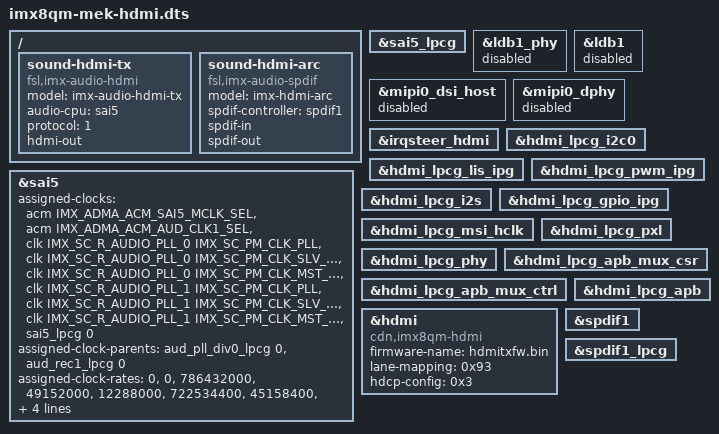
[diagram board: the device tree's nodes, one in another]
// SPDX-License-Identifier: GPL-2.0+
/*
 * Copyright 2019 NXP
 *	Sandor Yu <Sandor.yu@nxp.com>
 */
 /* HDMI, LVDS1 and MIPI DSI1. LVDS0 and MIPI0 are disabled */

/dts-v1/;

#include "imx8qm-mek-rpmsg.dts"

/ {
    sound-hdmi-tx {
        compatible = "fsl,imx-audio-hdmi";
        model = "imx-audio-hdmi-tx";
        audio-cpu = <&sai5>;
        protocol = <1>;
        hdmi-out;
    };

	sound-hdmi-arc {
		compatible = "fsl,imx-audio-spdif";
		model = "imx-hdmi-arc";
		spdif-controller = <&spdif1>;
		spdif-in;
		spdif-out;
	};
};

&sai5 {
	assigned-clocks = <&acm IMX_ADMA_ACM_SAI5_MCLK_SEL>,
			<&acm IMX_ADMA_ACM_AUD_CLK1_SEL>,
			<&clk IMX_SC_R_AUDIO_PLL_0 IMX_SC_PM_CLK_PLL>,
			<&clk IMX_SC_R_AUDIO_PLL_0 IMX_SC_PM_CLK_SLV_BUS>,
			<&clk IMX_SC_R_AUDIO_PLL_0 IMX_SC_PM_CLK_MST_BUS>,
			<&clk IMX_SC_R_AUDIO_PLL_1 IMX_SC_PM_CLK_PLL>,
			<&clk IMX_SC_R_AUDIO_PLL_1 IMX_SC_PM_CLK_SLV_BUS>,
			<&clk IMX_SC_R_AUDIO_PLL_1 IMX_SC_PM_CLK_MST_BUS>,
			<&sai5_lpcg 0>;
	assigned-clock-parents = <&aud_pll_div0_lpcg 0>, <&aud_rec1_lpcg 0>;
	assigned-clock-rates = <0>, <0>, <786432000>, <49152000>, <12288000>,
				 <722534400>, <45158400>, <11289600>,
				<49152000>;
	clocks = <&sai5_lpcg 1>,
		<&clk_dummy>,
		<&sai5_lpcg 0>,
		<&clk_dummy>,
		<&clk_dummy>,
		<&aud_pll_div0_lpcg 0>,
		<&aud_pll_div1_lpcg 0>;
	clock-names = "bus", "mclk0", "mclk1", "mclk2", "mclk3", "pll8k", "pll11k";
	status = "okay";
};

&sai5_lpcg {
	status = "okay";
};

&ldb1_phy {
	status = "disabled";
};

&ldb1 {
	status = "disabled";
};

&mipi0_dsi_host {
	status = "disabled";
};

&mipi0_dphy {
	status = "disabled";
};

&irqsteer_hdmi {
	status = "okay";
};

&hdmi_lpcg_i2c0 {
	status = "okay";
};

&hdmi_lpcg_lis_ipg {
	status = "okay";
};

&hdmi_lpcg_pwm_ipg {
	status = "okay";
};

&hdmi_lpcg_i2s {
	status = "okay";
};

&hdmi_lpcg_gpio_ipg {
	status = "okay";
};

&hdmi_lpcg_msi_hclk {
	status = "okay";
};

&hdmi_lpcg_pxl {
	status = "okay";
};

&hdmi_lpcg_phy {
	status = "okay";
};

&hdmi_lpcg_apb_mux_csr {
	status = "okay";
};

&hdmi_lpcg_apb_mux_ctrl {
	status = "okay";
};

&hdmi_lpcg_apb {
	status = "okay";
};

&hdmi {
	compatible = "cdn,imx8qm-hdmi";
	firmware-name = "hdmitxfw.bin";
	lane-mapping = <0x93>;
	hdcp-config = <0x3>;
	status = "okay";
};

&spdif1 {
	status = "okay";
};

&spdif1_lpcg {
	status = "okay";
};
